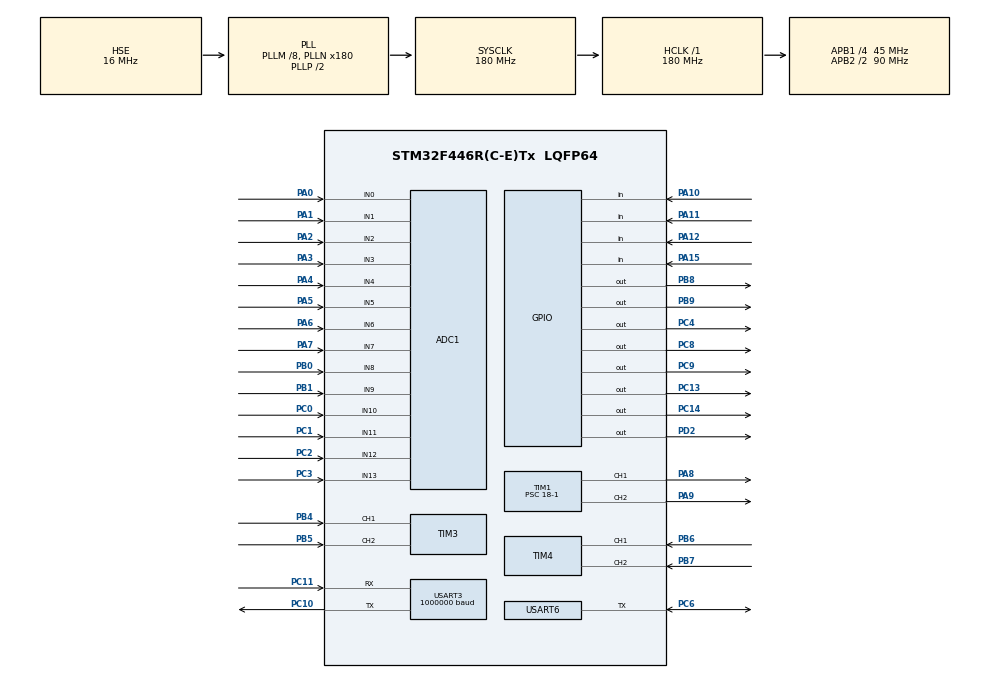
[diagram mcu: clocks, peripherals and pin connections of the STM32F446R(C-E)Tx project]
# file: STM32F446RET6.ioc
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ADC1.Channel-0\#ChannelRegularConversion=ADC_CHANNEL_0
ADC1.Channel-14\#ChannelRegularConversion=ADC_CHANNEL_1
ADC1.Channel-15\#ChannelRegularConversion=ADC_CHANNEL_2
ADC1.Channel-16\#ChannelRegularConversion=ADC_CHANNEL_3
ADC1.Channel-17\#ChannelRegularConversion=ADC_CHANNEL_4
ADC1.Channel-18\#ChannelRegularConversion=ADC_CHANNEL_5
ADC1.Channel-19\#ChannelRegularConversion=ADC_CHANNEL_6
ADC1.Channel-20\#ChannelRegularConversion=ADC_CHANNEL_7
ADC1.Channel-21\#ChannelRegularConversion=ADC_CHANNEL_8
ADC1.Channel-22\#ChannelRegularConversion=ADC_CHANNEL_9
ADC1.Channel-23\#ChannelRegularConversion=ADC_CHANNEL_10
ADC1.Channel-24\#ChannelRegularConversion=ADC_CHANNEL_11
ADC1.Channel-25\#ChannelRegularConversion=ADC_CHANNEL_12
ADC1.Channel-26\#ChannelRegularConversion=ADC_CHANNEL_13
ADC1.DMAContinuousRequests=ENABLE
ADC1.DiscontinuousConvMode=DISABLE
ADC1.ExternalTrigConv=ADC_EXTERNALTRIGCONV_T8_TRGO
ADC1.NbrOfConversion=14
ADC1.NbrOfConversionFlag=1
ADC1.Rank-0\#ChannelRegularConversion=1
ADC1.Rank-14\#ChannelRegularConversion=2
ADC1.Rank-15\#ChannelRegularConversion=3
ADC1.Rank-16\#ChannelRegularConversion=4
ADC1.Rank-17\#ChannelRegularConversion=5
ADC1.Rank-18\#ChannelRegularConversion=6
ADC1.Rank-19\#ChannelRegularConversion=7
ADC1.Rank-20\#ChannelRegularConversion=8
ADC1.Rank-21\#ChannelRegularConversion=9
ADC1.Rank-22\#ChannelRegularConversion=10
ADC1.Rank-23\#ChannelRegularConversion=11
ADC1.Rank-24\#ChannelRegularConversion=12
ADC1.Rank-25\#ChannelRegularConversion=13
ADC1.Rank-26\#ChannelRegularConversion=14
ADC1.SamplingTime-0\#ChannelRegularConversion=ADC_SAMPLETIME_15CYCLES
ADC1.SamplingTime-14\#ChannelRegularConversion=ADC_SAMPLETIME_15CYCLES
ADC1.SamplingTime-15\#ChannelRegularConversion=ADC_SAMPLETIME_15CYCLES
ADC1.SamplingTime-16\#ChannelRegularConversion=ADC_SAMPLETIME_15CYCLES
ADC1.SamplingTime-17\#ChannelRegularConversion=ADC_SAMPLETIME_15CYCLES
ADC1.SamplingTime-18\#ChannelRegularConversion=ADC_SAMPLETIME_15CYCLES
ADC1.SamplingTime-19\#ChannelRegularConversion=ADC_SAMPLETIME_15CYCLES
ADC1.SamplingTime-20\#ChannelRegularConversion=ADC_SAMPLETIME_15CYCLES
ADC1.SamplingTime-21\#ChannelRegularConversion=ADC_SAMPLETIME_15CYCLES
ADC1.SamplingTime-22\#ChannelRegularConversion=ADC_SAMPLETIME_15CYCLES
ADC1.SamplingTime-23\#ChannelRegularConversion=ADC_SAMPLETIME_15CYCLES
ADC1.SamplingTime-24\#ChannelRegularConversion=ADC_SAMPLETIME_15CYCLES
ADC1.SamplingTime-25\#ChannelRegularConversion=ADC_SAMPLETIME_15CYCLES
ADC1.SamplingTime-26\#ChannelRegularConversion=ADC_SAMPLETIME_15CYCLES
ADC1.ScanConvMode=ENABLE
ADC1.master=1
Dma.ADC1.0.Direction=DMA_PERIPH_TO_MEMORY
Dma.ADC1.0.FIFOMode=DMA_FIFOMODE_DISABLE
Dma.ADC1.0.Instance=DMA2_Stream0
Dma.ADC1.0.MemDataAlignment=DMA_MDATAALIGN_WORD
Dma.ADC1.0.MemInc=DMA_MINC_ENABLE
Dma.ADC1.0.Mode=DMA_CIRCULAR
Dma.ADC1.0.PeriphDataAlignment=DMA_PDATAALIGN_WORD
Dma.ADC1.0.PeriphInc=DMA_PINC_DISABLE
Dma.ADC1.0.Priority=DMA_PRIORITY_LOW
Dma.Request0=ADC1
Dma.Request1=USART6_RX
Dma.Request2=USART3_RX
Dma.USART3_RX.2.Direction=DMA_PERIPH_TO_MEMORY
Dma.USART3_RX.2.FIFOMode=DMA_FIFOMODE_DISABLE
Dma.USART3_RX.2.Instance=DMA1_Stream1
Dma.USART3_RX.2.MemDataAlignment=DMA_MDATAALIGN_BYTE
Dma.USART3_RX.2.MemInc=DMA_MINC_ENABLE
Dma.USART3_RX.2.Mode=DMA_CIRCULAR
Dma.USART3_RX.2.PeriphDataAlignment=DMA_PDATAALIGN_BYTE
Dma.USART3_RX.2.PeriphInc=DMA_PINC_DISABLE
Dma.USART3_RX.2.Priority=DMA_PRIORITY_LOW
Dma.USART6_RX.1.Direction=DMA_PERIPH_TO_MEMORY
Dma.USART6_RX.1.FIFOMode=DMA_FIFOMODE_DISABLE
Dma.USART6_RX.1.Instance=DMA2_Stream1
Dma.USART6_RX.1.MemDataAlignment=DMA_MDATAALIGN_BYTE
Dma.USART6_RX.1.MemInc=DMA_MINC_ENABLE
Dma.USART6_RX.1.Mode=DMA_CIRCULAR
Dma.USART6_RX.1.PeriphDataAlignment=DMA_PDATAALIGN_BYTE
Dma.USART6_RX.1.PeriphInc=DMA_PINC_DISABLE
Dma.USART6_RX.1.Priority=DMA_PRIORITY_LOW
Mcu.Family=STM32F4
Mcu.Name=STM32F446R(C-E)Tx
Mcu.Package=LQFP64
NVIC.ADC_IRQn=true\:0\:0\:false\:false\:true\:true\:true\:true
NVIC.DMA1_Stream1_IRQn=true\:0\:0\:false\:false\:true\:false\:true\:true
NVIC.DMA2_Stream0_IRQn=true\:0\:0\:false\:false\:true\:false\:true\:true
NVIC.DMA2_Stream1_IRQn=true\:0\:0\:false\:false\:true\:false\:true\:true
NVIC.PriorityGroup=NVIC_PRIORITYGROUP_4
NVIC.TIM1_BRK_TIM9_IRQn=true\:0\:0\:false\:false\:true\:true\:true\:true
NVIC.TIM1_CC_IRQn=true\:0\:0\:false\:false\:true\:true\:true\:true
NVIC.TIM1_TRG_COM_TIM11_IRQn=true\:0\:0\:false\:false\:true\:true\:true\:true
NVIC.TIM1_UP_TIM10_IRQn=true\:0\:0\:false\:false\:true\:true\:true\:true
NVIC.TIM6_DAC_IRQn=true\:0\:0\:false\:false\:true\:true\:true\:true
NVIC.TIM8_UP_TIM13_IRQn=true\:0\:0\:false\:false\:true\:true\:true\:true
NVIC.USART3_IRQn=true\:0\:0\:false\:false\:true\:true\:true\:true
NVIC.USART6_IRQn=true\:0\:0\:false\:false\:true\:true\:true\:true
PA0-WKUP.Signal=ADCx_IN0
PA1.Signal=ADCx_IN1
PA10.Signal=GPIO_Input
PA11.Signal=GPIO_Input
PA12.Signal=GPIO_Input
PA13.Mode=Serial_Wire
PA13.Signal=SYS_JTMS-SWDIO
PA14.Mode=Serial_Wire
PA14.Signal=SYS_JTCK-SWCLK
PA15.Signal=GPIO_Input
PA2.Signal=ADCx_IN2
PA3.Signal=ADCx_IN3
PA4.Signal=ADCx_IN4
PA5.Signal=ADCx_IN5
PA6.Signal=ADCx_IN6
PA7.Signal=ADCx_IN7
PA8.Signal=S_TIM1_CH1
PA9.Signal=S_TIM1_CH2
PB0.Signal=ADCx_IN8
PB1.Signal=ADCx_IN9
PB4.GPIO_PuPd=GPIO_PULLUP
PB4.Signal=S_TIM3_CH1
PB5.GPIO_PuPd=GPIO_PULLUP
PB5.Signal=S_TIM3_CH2
PB6.GPIO_PuPd=GPIO_PULLUP
PB6.Signal=S_TIM4_CH1
PB7.GPIO_PuPd=GPIO_PULLUP
PB7.Signal=S_TIM4_CH2
PB8.Signal=GPIO_Output
PB9.Signal=GPIO_Output
PC0.Signal=ADCx_IN10
PC1.Signal=ADCx_IN11
PC10.Mode=Asynchronous
PC10.Signal=USART3_TX
PC11.Mode=Asynchronous
PC11.Signal=USART3_RX
PC13.Signal=GPIO_Output
PC14-OSC32_IN.Signal=GPIO_Output
PC2.Signal=ADCx_IN12
PC3.Signal=ADCx_IN13
PC4.Signal=GPIO_Output
PC6.Mode=Half_duplex(single_wire_mode)
PC6.Signal=USART6_TX
PC7.Signal=USART6_RX
PC8.Signal=GPIO_Output
PC9.Signal=GPIO_Output
PD2.Signal=GPIO_Output
PH0-OSC_IN.Mode=HSE-External-Oscillator
PH0-OSC_IN.Signal=RCC_OSC_IN
PH1-OSC_OUT.Mode=HSE-External-Oscillator
PH1-OSC_OUT.Signal=RCC_OSC_OUT
ProjectManager.HeapSize=0x200
ProjectManager.StackSize=0x400
ProjectManager.TargetToolchain=STM32CubeIDE
RCC.AHBFreq_Value=180000000
RCC.APB1CLKDivider=RCC_HCLK_DIV4
RCC.APB1Freq_Value=45000000
RCC.APB1TimFreq_Value=90000000
RCC.APB2CLKDivider=RCC_HCLK_DIV2
RCC.APB2Freq_Value=90000000
RCC.APB2TimFreq_Value=180000000
RCC.CortexFreq_Value=180000000
RCC.HCLKFreq_Value=180000000
RCC.HSE_VALUE=16000000
RCC.PLLM=8
RCC.PLLN=180
RCC.PLLSourceVirtual=RCC_PLLSOURCE_HSE
RCC.SYSCLKFreq_VALUE=180000000
RCC.SYSCLKSource=RCC_SYSCLKSOURCE_PLLCLK
RCC.USBFreq_Value=180000000
RCC.VCOOutputFreq_Value=360000000
SH.ADCx_IN0.0=ADC1_IN0,IN0
SH.ADCx_IN1.0=ADC1_IN1,IN1
SH.ADCx_IN10.0=ADC1_IN10,IN10
SH.ADCx_IN11.0=ADC1_IN11,IN11
SH.ADCx_IN12.0=ADC1_IN12,IN12
SH.ADCx_IN13.0=ADC1_IN13,IN13
SH.ADCx_IN2.0=ADC1_IN2,IN2
SH.ADCx_IN3.0=ADC1_IN3,IN3
SH.ADCx_IN4.0=ADC1_IN4,IN4
SH.ADCx_IN5.0=ADC1_IN5,IN5
SH.ADCx_IN6.0=ADC1_IN6,IN6
SH.ADCx_IN7.0=ADC1_IN7,IN7
SH.ADCx_IN8.0=ADC1_IN8,IN8
SH.ADCx_IN9.0=ADC1_IN9,IN9
SH.S_TIM1_CH1.0=TIM1_CH1,PWM Generation1 CH1
SH.S_TIM1_CH2.0=TIM1_CH2,PWM Generation2 CH2
SH.S_TIM3_CH1.0=TIM3_CH1,Encoder_Interface
SH.S_TIM3_CH2.0=TIM3_CH2,Encoder_Interface
SH.S_TIM4_CH1.0=TIM4_CH1,Encoder_Interface
SH.S_TIM4_CH2.0=TIM4_CH2,Encoder_Interface
TIM1.Channel-PWM\ Generation1\ CH1=TIM_CHANNEL_1
TIM1.Channel-PWM\ Generation2\ CH2=TIM_CHANNEL_2
TIM1.OCMode_PWM-PWM\ Generation2\ CH2=TIM_OCMODE_PWM1
TIM1.Period=1000-1
TIM1.Prescaler=18-1
TIM3.EncoderMode=TIM_ENCODERMODE_TI12
TIM3.IC1Filter=5
TIM3.IC2Filter=5
TIM4.EncoderMode=TIM_ENCODERMODE_TI12
TIM4.IC1Filter=5
TIM4.IC2Filter=5
TIM6.Period=100-1
TIM6.Prescaler=90-1
TIM8.Period=1000-1
TIM8.Prescaler=180-1
TIM8.TIM_MasterOutputTrigger=TIM_TRGO_UPDATE
USART3.BaudRate=1000000
USART3.VirtualMode=VM_ASYNC
USART6.VirtualMode=VM_ASYNC
VP_TIM1_VS_ClockSourceINT.Mode=Internal
VP_TIM6_VS_ClockSourceINT.Mode=Enable_Timer
VP_TIM8_VS_ClockSourceINT.Mode=Internal
board=custom

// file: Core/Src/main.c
/* USER CODE BEGIN Header */
/**
  ******************************************************************************
  * @file           : main.c
  * @brief          : Main program body
  ******************************************************************************
  * @attention
  *
  * Copyright (c) 2025 STMicroelectronics.
  * All rights reserved.
  *
  * This software is licensed under terms that can be found in the LICENSE file
  * in the root directory of this software component.
  * If no LICENSE file comes with this software, it is provided AS-IS.
  *
  ******************************************************************************
  */
/* USER CODE END Header */
#include "main.h"
#include "adc.h"
#include "dma.h"
#include "tim.h"
#include "usart.h"
#include "gpio.h"

/* USER CODE BEGIN Includes */
#include "usart.h"
#include "dma.h"
/* USER CODE END Includes */

/* USER CODE BEGIN PV */
//uint32_t adc_buffer[14] = {0, };
//uint32_t test_value = 0;
//uint8_t rx_buffer[256];
//float encoder1_value = 0;
//float encoder2_value = 0;
//uint16_t timer_encoder;

/* USER CODE END PV */

void SystemClock_Config(void);

/* USER CODE BEGIN 0 */
//void HAL_TIM_PeriodElapsedCallback(TIM_HandleTypeDef *htim) {
//	timer_encoder = __HAL_TIM_GET_COUNTER(&htim3);
//}

/* USER CODE END 0 */

int main(void)
{

  /* MCU Configuration--------------------------------------------------------*/

  /* Reset of all peripherals, Initializes the Flash interface and the Systick. */
  HAL_Init();

  /* Configure the system clock */
  SystemClock_Config();

  /* Initialize all configured peripherals */
  MX_GPIO_Init();
  MX_DMA_Init();
  MX_ADC1_Init();
  MX_TIM8_Init();
  MX_TIM6_Init();
  MX_USART6_UART_Init();
  MX_TIM1_Init();
  MX_TIM3_Init();
  MX_TIM4_Init();
  MX_USART3_UART_Init();
  /* USER CODE BEGIN 2 */
  HAL_TIM_Base_Start_IT(&htim8);
  HAL_TIM_Base_Start_IT(&htim6);

  HAL_TIM_PWM_Start(&htim1, TIM_CHANNEL_1);
  HAL_TIM_PWM_Start(&htim1, TIM_CHANNEL_2);
  HAL_TIMEx_PWMN_Start(&htim1, TIM_CHANNEL_1);
  HAL_TIMEx_PWMN_Start(&htim1, TIM_CHANNEL_2);

  // Encoder 관련 설정
  HAL_TIM_Encoder_Start(&htim3, TIM_CHANNEL_ALL);
  HAL_TIM_Encoder_Start(&htim4, TIM_CHANNEL_ALL);

  /* USER CODE END 2 */

  /* Infinite loop */
  while (1)
  {

    /* USER CODE BEGIN 3 */
//	  if(HAL_GPIO_ReadPin(GPIOA, GPIO_PIN_10)) {
//		  HAL_GPIO_WritePin(GPIOB, GPIO_PIN_8, 1);
//	  } else {
//		  HAL_GPIO_WritePin(GPIOB, GPIO_PIN_8, 0);
//	  }
//
//	  if(HAL_GPIO_ReadPin(GPIOA, GPIO_PIN_11)) {
//		  HAL_GPIO_WritePin(GPIOB, GPIO_PIN_9, 1);
//	  } else {
//		  HAL_GPIO_WritePin(GPIOB, GPIO_PIN_9, 0);
//	  }
//
//	  if(HAL_GPIO_ReadPin(GPIOA, GPIO_PIN_12)) {
//		  HAL_GPIO_WritePin(GPIOC, GPIO_PIN_14, 1);
//	  } else {
//		  HAL_GPIO_WritePin(GPIOC, GPIO_PIN_14, 0);
//	  }
//
//	  if(HAL_GPIO_ReadPin(GPIOA, GPIO_PIN_15)) {
//		  HAL_GPIO_WritePin(GPIOC, GPIO_PIN_13, 1);
//	  } else {
//		  HAL_GPIO_WritePin(GPIOC, GPIO_PIN_13 , 0);
//	  }
//
//	  TIM1->CCR1 = 0;
//	  TIM1->CCR2 = 0;
//	  encoder1_value = TIM3->CNT;
//	  encoder2_value = TIM4->CNT;
//	  HAL_Delay(500);
//	  TIM1->CCR1 = 150;
//	  TIM1->CCR2 = 150;
//	  encoder1_value = TIM3->CNT;
//	  encoder2_value = TIM4->CNT;
//	  HAL_Delay(500);
//	  TIM1->CCR1 = 300;
//	  TIM1->CCR2 = 300;
//	  encoder1_value = TIM3->CNT;
//	  encoder2_value = TIM4->CNT;
//	  HAL_Delay(500);
//	  TIM1->CCR1 = 500;
//	  TIM1->CCR2 = 500;
//	  encoder1_value = TIM3->CNT;
//	  encoder2_value = TIM4->CNT;
//	  HAL_Delay(500);

  }
  /* USER CODE END 3 */
}

void SystemClock_Config(void)
{
  RCC_OscInitTypeDef RCC_OscInitStruct = {0};
  RCC_ClkInitTypeDef RCC_ClkInitStruct = {0};

  /** Configure the main internal regulator output voltage
  */
  __HAL_RCC_PWR_CLK_ENABLE();
  __HAL_PWR_VOLTAGESCALING_CONFIG(PWR_REGULATOR_VOLTAGE_SCALE1);

  /** Initializes the RCC Oscillators according to the specified parameters
  * in the RCC_OscInitTypeDef structure.
  */
  RCC_OscInitStruct.OscillatorType = RCC_OSCILLATORTYPE_HSE;
  RCC_OscInitStruct.HSEState = RCC_HSE_ON;
  RCC_OscInitStruct.PLL.PLLState = RCC_PLL_ON;
  RCC_OscInitStruct.PLL.PLLSource = RCC_PLLSOURCE_HSE;
  RCC_OscInitStruct.PLL.PLLM = 8;
  RCC_OscInitStruct.PLL.PLLN = 180;
  RCC_OscInitStruct.PLL.PLLP = RCC_PLLP_DIV2;
  RCC_OscInitStruct.PLL.PLLQ = 2;
  RCC_OscInitStruct.PLL.PLLR = 2;
  if (HAL_RCC_OscConfig(&RCC_OscInitStruct) != HAL_OK)
  {
    Error_Handler();
  }

  /** Activate the Over-Drive mode
  */
  if (HAL_PWREx_EnableOverDrive() != HAL_OK)
  {
    Error_Handler();
  }

  /** Initializes the CPU, AHB and APB buses clocks
  */
  RCC_ClkInitStruct.ClockType = RCC_CLOCKTYPE_HCLK|RCC_CLOCKTYPE_SYSCLK
                              |RCC_CLOCKTYPE_PCLK1|RCC_CLOCKTYPE_PCLK2;
  RCC_ClkInitStruct.SYSCLKSource = RCC_SYSCLKSOURCE_PLLCLK;
  RCC_ClkInitStruct.AHBCLKDivider = RCC_SYSCLK_DIV1;
  RCC_ClkInitStruct.APB1CLKDivider = RCC_HCLK_DIV4;
  RCC_ClkInitStruct.APB2CLKDivider = RCC_HCLK_DIV2;

  if (HAL_RCC_ClockConfig(&RCC_ClkInitStruct, FLASH_LATENCY_5) != HAL_OK)
  {
    Error_Handler();
  }
}

void Error_Handler(void)
{
  __disable_irq();
  while (1)
  {
  }
}
